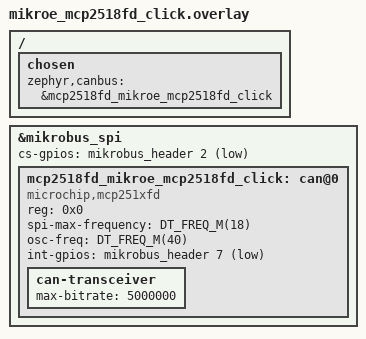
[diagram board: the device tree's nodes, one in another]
/*
 * SPDX-FileCopyrightText: Copyright (c) 2026 Henrik Brix Andersen <henrik@brixandersen.dk>
 * SPDX-FileCopyrightText: Copyright (c) 2023 Andriy Gelman
 * SPDX-License-Identifier: Apache-2.0
 */

#include <zephyr/dt-bindings/gpio/gpio.h>
#include <freq.h>

/ {
	chosen {
		zephyr,canbus = &mcp2518fd_mikroe_mcp2518fd_click;
	};
};

&mikrobus_spi {
	cs-gpios = <&mikrobus_header 2 GPIO_ACTIVE_LOW>;

	mcp2518fd_mikroe_mcp2518fd_click: can@0 {
		compatible = "microchip,mcp251xfd";
		reg = <0x0>;
		spi-max-frequency = <DT_FREQ_M(18)>;
		osc-freq = <DT_FREQ_M(40)>;
		int-gpios = <&mikrobus_header 7 GPIO_ACTIVE_LOW>;
		status = "okay";

		can-transceiver {
			max-bitrate = <5000000>;
		};
	};
};
